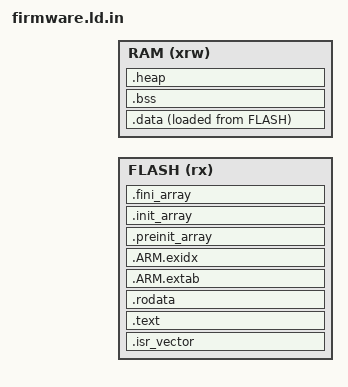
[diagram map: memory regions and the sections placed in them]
/* Generated per target. Edit this template and config/flash_layout.json. */
ENTRY(Reset_Handler)
MEMORY
{
    FLASH (rx)  : ORIGIN = @IMAGE_ORIGIN@, LENGTH = @IMAGE_SIZE@
    RAM   (xrw) : ORIGIN = @COURSE_RAM_BASE@, LENGTH = @COURSE_RAM_SIZE@
}
_estack = ORIGIN(RAM) + LENGTH(RAM);
_Min_Heap_Size = 0x200;
_Min_Stack_Size = 0x800;
__StackLimit = _estack - _Min_Stack_Size;
SECTIONS
{
    .isr_vector : { . = ALIGN(512); KEEP(*(.isr_vector)) . = ALIGN(4); } > FLASH
    .text :
    {
        . = ALIGN(4);
        *(.text .text.*) *(.glue_7 .glue_7t)
        KEEP(*(.init)) KEEP(*(.fini))
        . = ALIGN(4);
    } > FLASH
    .rodata : { . = ALIGN(4); *(.rodata .rodata.*) *(.eh_frame .eh_frame.*) . = ALIGN(4); } > FLASH
    .ARM.extab (READONLY) : { . = ALIGN(4); *(.ARM.extab* .gnu.linkonce.armextab.*) . = ALIGN(4); } > FLASH
    .ARM.exidx (READONLY) :
    {
        __exidx_start = .; *(.ARM.exidx* .gnu.linkonce.armexidx.*) __exidx_end = .;
    } > FLASH
    .preinit_array (READONLY) :
    {
        . = ALIGN(4); PROVIDE_HIDDEN(__preinit_array_start = .);
        KEEP(*(.preinit_array*)) PROVIDE_HIDDEN(__preinit_array_end = .);
    } > FLASH
    .init_array (READONLY) :
    {
        . = ALIGN(4); PROVIDE_HIDDEN(__init_array_start = .);
        KEEP(*(SORT_BY_INIT_PRIORITY(.init_array.*))) KEEP(*(.init_array))
        PROVIDE_HIDDEN(__init_array_end = .);
    } > FLASH
    .fini_array (READONLY) :
    {
        . = ALIGN(4); PROVIDE_HIDDEN(__fini_array_start = .);
        KEEP(*(SORT_BY_INIT_PRIORITY(.fini_array.*))) KEEP(*(.fini_array))
        PROVIDE_HIDDEN(__fini_array_end = .); . = ALIGN(4); _etext = .;
    } > FLASH
    _sidata = LOADADDR(.data);
    .data :
    {
        . = ALIGN(4); _sdata = .;
        *(.data .data.*) *(.RamFunc .RamFunc.*)
        . = ALIGN(4); _edata = .;
    } > RAM AT > FLASH
    .bss (NOLOAD) :
    {
        . = ALIGN(4); _sbss = .; __bss_start__ = .;
        *(.bss .bss.*) *(COMMON)
        . = ALIGN(4); _ebss = .; __bss_end__ = .;
    } > RAM
    .heap (NOLOAD) :
    {
        . = ALIGN(8); PROVIDE(end = .); PROVIDE(_end = .);
        . += _Min_Heap_Size; . = ALIGN(8); __HeapLimit = .;
    } > RAM
    .ARM.attributes 0 : { *(.ARM.attributes) }
    /DISCARD/ : { *(.note.GNU-stack) }
}
ASSERT(ADDR(.isr_vector) == ORIGIN(FLASH), "Vector table must start at image base")
ASSERT((ORIGIN(FLASH) % 512) == 0, "Vector table alignment")
ASSERT(__HeapLimit <= __StackLimit, "Data/heap overlap reserved stack")
